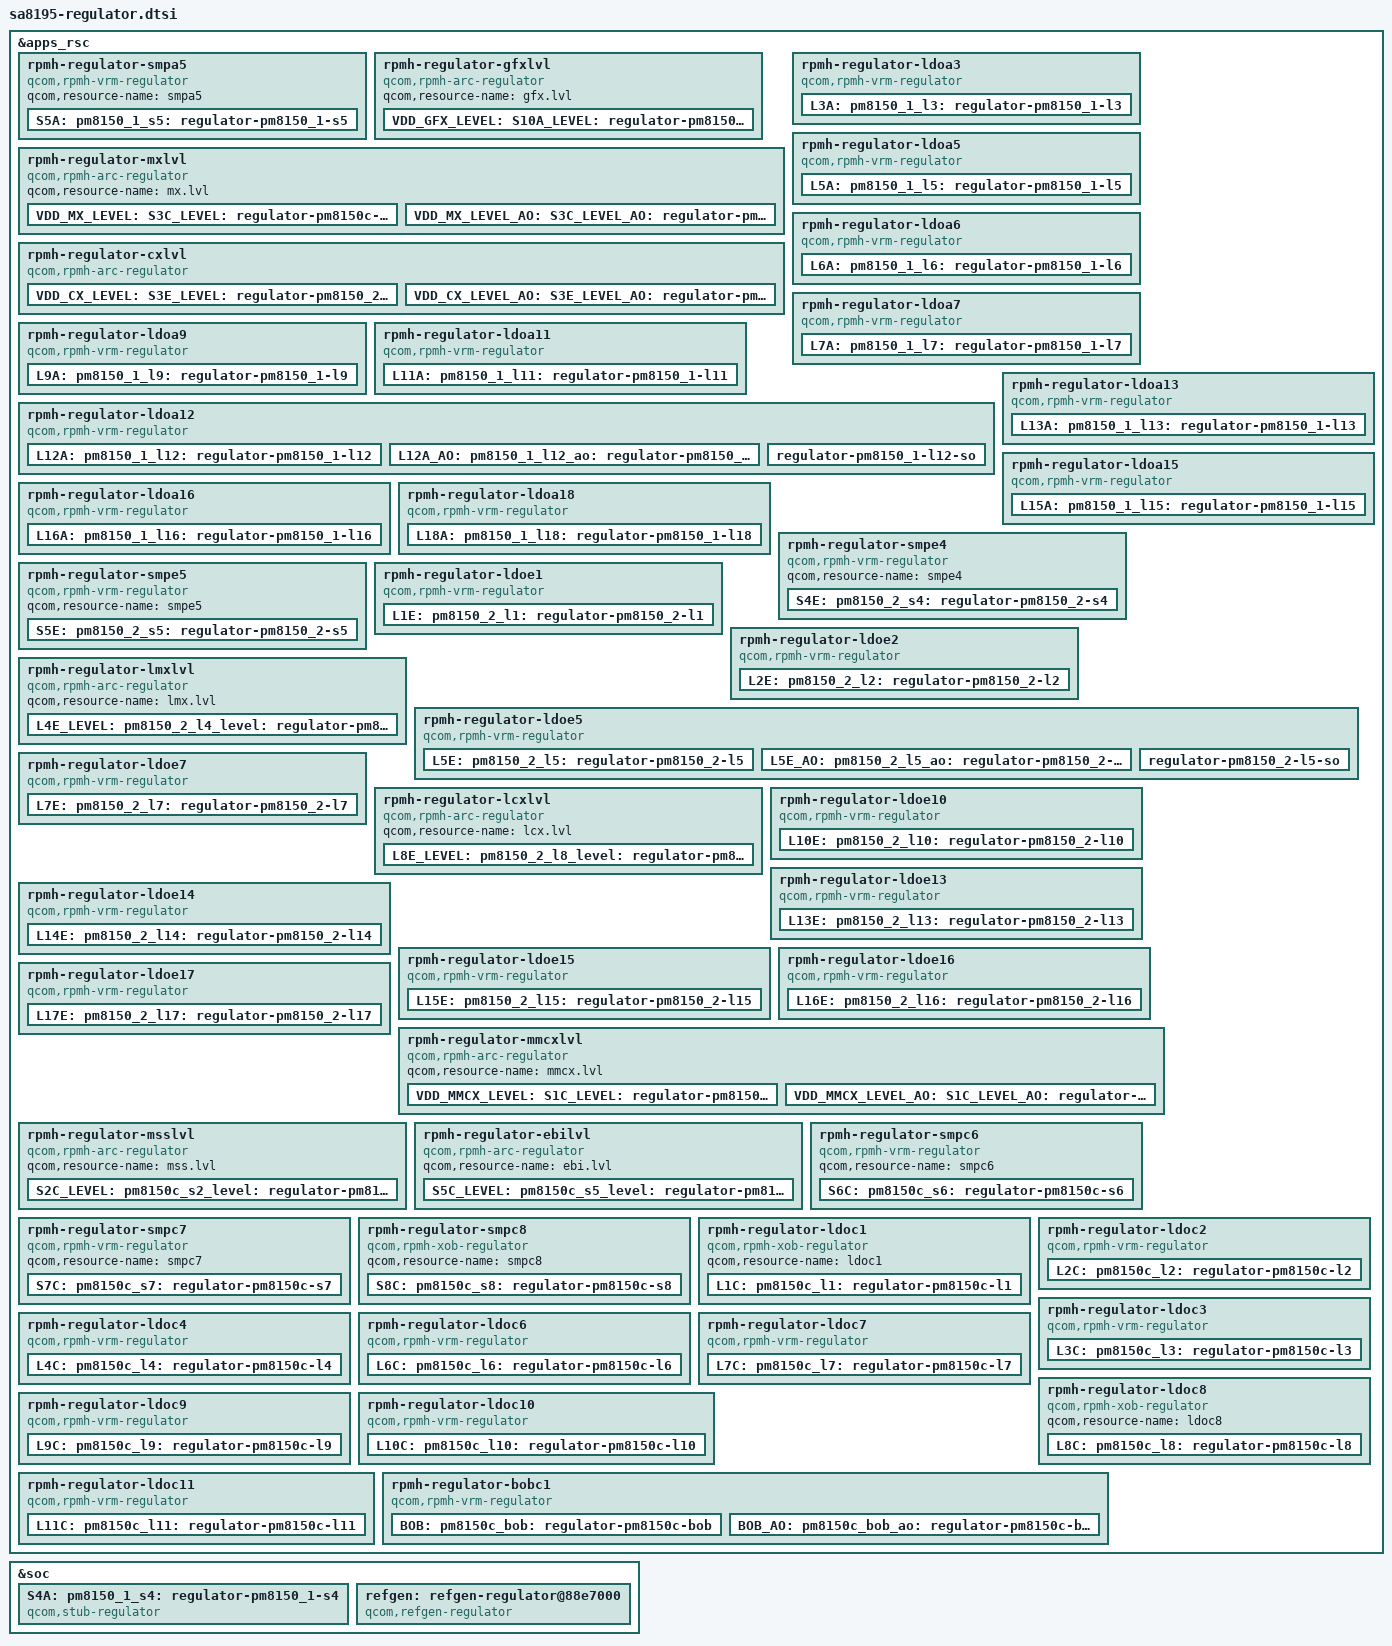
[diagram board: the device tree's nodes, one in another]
#include <dt-bindings/regulator/qcom,rpmh-regulator-levels.h>

&apps_rsc {
	/* PM8150_1 regulators */
	rpmh-regulator-smpa5 {
		compatible = "qcom,rpmh-vrm-regulator";
		qcom,resource-name = "smpa5";
		S5A: pm8150_1_s5: regulator-pm8150_1-s5 {
			regulator-name = "pm8150_1_s5";
			qcom,set = <RPMH_REGULATOR_SET_ALL>;
			regulator-min-microvolt = <1824000>;
			regulator-max-microvolt = <2040000>;
			qcom,init-voltage = <1824000>;
		};
	};

	/* PM8150_1 S10 + S9 + S8 + S7 + S6 = VDD_GFX */
	rpmh-regulator-gfxlvl {
		compatible = "qcom,rpmh-arc-regulator";
		qcom,resource-name = "gfx.lvl";
		VDD_GFX_LEVEL:
		S10A_LEVEL: pm8150_1_s10_level: regulator-pm8150_1-s10-level {
			regulator-name = "pm8150_1_s10_level";
			qcom,set = <RPMH_REGULATOR_SET_ALL>;
			regulator-min-microvolt
				= <RPMH_REGULATOR_LEVEL_RETENTION>;
			regulator-max-microvolt
				= <RPMH_REGULATOR_LEVEL_MAX>;
			qcom,init-voltage-level
				= <RPMH_REGULATOR_LEVEL_RETENTION>;
		};
	};

	/* PM8150C S3 + S4 = VDD_MX supply */
	rpmh-regulator-mxlvl {
		compatible = "qcom,rpmh-arc-regulator";
		qcom,resource-name = "mx.lvl";

		VDD_MX_LEVEL: S3C_LEVEL:
		pm8150c_s3_level: regulator-pm8150c-s3-level {
			regulator-name = "pm8150c_s3_level";
			qcom,set = <RPMH_REGULATOR_SET_ALL>;
			regulator-min-microvolt
				= <RPMH_REGULATOR_LEVEL_RETENTION>;
			regulator-max-microvolt
				= <RPMH_REGULATOR_LEVEL_MAX>;
			qcom,init-voltage-level
				= <RPMH_REGULATOR_LEVEL_RETENTION>;
		};

		VDD_MX_LEVEL_AO: S3C_LEVEL_AO:
		pm8150c_s3_level_ao: regulator-pm8150c-s3-level-ao {
			regulator-name = "pm8150c_s3_level_ao";
			qcom,set = <RPMH_REGULATOR_SET_ACTIVE>;
			regulator-min-microvolt
				= <RPMH_REGULATOR_LEVEL_RETENTION>;
			regulator-max-microvolt
				= <RPMH_REGULATOR_LEVEL_MAX>;
			qcom,init-voltage-level
				= <RPMH_REGULATOR_LEVEL_RETENTION>;
		};
	};

	/* PM8150_2 regulators */
	/* PM8150_2 S3 + S2 + S1 = VDD_CX supply */
	rpmh-regulator-cxlvl {
		compatible = "qcom,rpmh-arc-regulator";
		qcom,resource-name = "cx.lvl";
		pm8150_2_s3_level-parent-supply = <&VDD_MX_LEVEL>;
		pm8150_2_s3_level_ao-parent-supply = <&VDD_MX_LEVEL_AO>;

		VDD_CX_LEVEL: S3E_LEVEL:
		pm8150_2_s3_level: regulator-pm8150_2-s3-level {
			regulator-name = "pm8150_2_s3_level";
			qcom,set = <RPMH_REGULATOR_SET_ALL>;
			regulator-min-microvolt
				= <RPMH_REGULATOR_LEVEL_RETENTION>;
			regulator-max-microvolt
				= <RPMH_REGULATOR_LEVEL_MAX>;
			qcom,init-voltage-level
				= <RPMH_REGULATOR_LEVEL_RETENTION>;
			qcom,min-dropout-voltage-level = <(-1)>;
		};

		VDD_CX_LEVEL_AO: S3E_LEVEL_AO:
		pm8150_2_s3_level_ao: regulator-pm8150_2-s3-level-ao {
			regulator-name = "pm8150_2_s3_level_ao";
			qcom,set = <RPMH_REGULATOR_SET_ACTIVE>;
			regulator-min-microvolt
				= <RPMH_REGULATOR_LEVEL_RETENTION>;
			regulator-max-microvolt
				= <RPMH_REGULATOR_LEVEL_MAX>;
			qcom,init-voltage-level
				= <RPMH_REGULATOR_LEVEL_RETENTION>;
			qcom,min-dropout-voltage-level = <(-1)>;
		};
	};

	rpmh-regulator-ldoa3 {
		compatible = "qcom,rpmh-vrm-regulator";
		qcom,resource-name = "ldoa3";
		qcom,regulator-type = "pmic5-ldo";
		qcom,supported-modes =
			<RPMH_REGULATOR_MODE_LPM
			RPMH_REGULATOR_MODE_HPM>;
		qcom,mode-threshold-currents = <0 10000>;
		L3A: pm8150_1_l3: regulator-pm8150_1-l3 {
			regulator-name = "pm8150_1_l3";
			qcom,set = <RPMH_REGULATOR_SET_ALL>;
			regulator-min-microvolt = <800000>;
			regulator-max-microvolt = <800000>;
			qcom,init-voltage = <800000>;
			qcom,init-mode = <RPMH_REGULATOR_MODE_LPM>;
		};
	};

	rpmh-regulator-ldoa5 {
		compatible = "qcom,rpmh-vrm-regulator";
		qcom,resource-name = "ldoa5";
		qcom,regulator-type = "pmic5-ldo";
		qcom,supported-modes =
			<RPMH_REGULATOR_MODE_LPM
			RPMH_REGULATOR_MODE_HPM>;
		qcom,mode-threshold-currents = <0 1>;
		L5A: pm8150_1_l5: regulator-pm8150_1-l5 {
			regulator-name = "pm8150_1_l5";
			qcom,set = <RPMH_REGULATOR_SET_ALL>;
			regulator-min-microvolt = <480000>;
			regulator-max-microvolt = <932000>;
			qcom,init-voltage = <480000>;
			qcom,init-mode = <RPMH_REGULATOR_MODE_LPM>;
		};
	};

	rpmh-regulator-ldoa6 {
		compatible = "qcom,rpmh-vrm-regulator";
		qcom,resource-name = "ldoa6";
		qcom,regulator-type = "pmic5-ldo";
		qcom,supported-modes =
			<RPMH_REGULATOR_MODE_LPM
			RPMH_REGULATOR_MODE_HPM>;
		qcom,mode-threshold-currents = <0 10000>;
		L6A: pm8150_1_l6: regulator-pm8150_1-l6 {
			regulator-name = "pm8150_1_l6";
			qcom,set = <RPMH_REGULATOR_SET_ALL>;
			regulator-min-microvolt = <1200000>;
			regulator-max-microvolt = <1200000>;
			qcom,init-voltage = <1200000>;
			qcom,init-mode = <RPMH_REGULATOR_MODE_LPM>;
		};
	};

	rpmh-regulator-ldoa7 {
		compatible = "qcom,rpmh-vrm-regulator";
		qcom,resource-name = "ldoa7";
		qcom,regulator-type = "pmic5-ldo";
		qcom,supported-modes =
			<RPMH_REGULATOR_MODE_LPM
			RPMH_REGULATOR_MODE_HPM>;
		qcom,mode-threshold-currents = <0 1>;
		L7A: pm8150_1_l7: regulator-pm8150_1-l7 {
			regulator-name = "pm8150_1_l7";
			qcom,set = <RPMH_REGULATOR_SET_ALL>;
			regulator-min-microvolt = <1800000>;
			regulator-max-microvolt = <1800000>;
			qcom,init-voltage = <1800000>;
			qcom,init-mode = <RPMH_REGULATOR_MODE_LPM>;
		};
	};

	rpmh-regulator-ldoa9 {
		compatible = "qcom,rpmh-vrm-regulator";
		qcom,resource-name = "ldoa9";
		qcom,regulator-type = "pmic5-ldo";
		qcom,supported-modes =
			<RPMH_REGULATOR_MODE_LPM
			RPMH_REGULATOR_MODE_HPM>;
		qcom,mode-threshold-currents = <0 1>;
		L9A: pm8150_1_l9: regulator-pm8150_1-l9 {
			regulator-name = "pm8150_1_l9";
			qcom,set = <RPMH_REGULATOR_SET_ALL>;
			regulator-min-microvolt = <1304000>;
			regulator-max-microvolt = <1304000>;
			qcom,init-voltage = <1304000>;
			qcom,init-mode = <RPMH_REGULATOR_MODE_LPM>;
		};
	};

	rpmh-regulator-ldoa11 {
		compatible = "qcom,rpmh-vrm-regulator";
		qcom,resource-name = "ldoa11";
		qcom,regulator-type = "pmic5-ldo";
		qcom,supported-modes =
			<RPMH_REGULATOR_MODE_LPM
			RPMH_REGULATOR_MODE_HPM>;
		qcom,mode-threshold-currents = <0 10000>;
		L11A: pm8150_1_l11: regulator-pm8150_1-l11 {
			regulator-name = "pm8150_1_l11";
			qcom,set = <RPMH_REGULATOR_SET_ALL>;
			regulator-min-microvolt = <1200000>;
			regulator-max-microvolt = <1200000>;
			qcom,init-voltage = <1200000>;
			qcom,init-mode = <RPMH_REGULATOR_MODE_LPM>;
		};
	};

	rpmh-regulator-ldoa12 {
		compatible = "qcom,rpmh-vrm-regulator";
		qcom,resource-name = "ldoa12";
		qcom,regulator-type = "pmic5-ldo";
		qcom,supported-modes =
			<RPMH_REGULATOR_MODE_LPM
			RPMH_REGULATOR_MODE_HPM>;
		qcom,mode-threshold-currents = <0 1>;
		L12A: pm8150_1_l12: regulator-pm8150_1-l12 {
			regulator-name = "pm8150_1_l12";
			qcom,set = <RPMH_REGULATOR_SET_ALL>;
			regulator-min-microvolt = <1800000>;
			regulator-max-microvolt = <1800000>;
			qcom,init-voltage = <1800000>;
			qcom,init-mode = <RPMH_REGULATOR_MODE_LPM>;
		};

		L12A_AO: pm8150_1_l12_ao: regulator-pm8150_1-l12-ao {
			regulator-name = "pm8150_1_l12_ao";
			qcom,set = <RPMH_REGULATOR_SET_ACTIVE>;
			regulator-min-microvolt = <1800000>;
			regulator-max-microvolt = <1800000>;
			qcom,init-voltage = <1800000>;
			qcom,init-mode = <RPMH_REGULATOR_MODE_LPM>;
		};

		regulator-pm8150_1-l12-so {
			regulator-name = "pm8150_1_l12_so";
			qcom,set = <RPMH_REGULATOR_SET_SLEEP>;
			regulator-min-microvolt = <1800000>;
			regulator-max-microvolt = <1800000>;
			qcom,init-voltage = <1800000>;
			qcom,init-mode = <RPMH_REGULATOR_MODE_LPM>;
			qcom,init-enable = <0>;
		};
	};

	rpmh-regulator-ldoa13 {
		compatible = "qcom,rpmh-vrm-regulator";
		qcom,resource-name = "ldoa13";
		qcom,regulator-type = "pmic5-ldo";
		qcom,supported-modes =
			<RPMH_REGULATOR_MODE_LPM
			RPMH_REGULATOR_MODE_HPM>;
		qcom,mode-threshold-currents = <0 1>;
		L13A: pm8150_1_l13: regulator-pm8150_1-l13 {
			regulator-name = "pm8150_1_l13";
			qcom,set = <RPMH_REGULATOR_SET_ALL>;
			regulator-min-microvolt = <2704000>;
			regulator-max-microvolt = <2704000>;
			qcom,init-voltage = <2704000>;
			qcom,init-mode = <RPMH_REGULATOR_MODE_LPM>;
		};
	};

	rpmh-regulator-ldoa15 {
		compatible = "qcom,rpmh-vrm-regulator";
		qcom,resource-name = "ldoa15";
		qcom,regulator-type = "pmic5-ldo";
		qcom,supported-modes =
			<RPMH_REGULATOR_MODE_LPM
			RPMH_REGULATOR_MODE_HPM>;
		qcom,mode-threshold-currents = <0 1>;
		L15A: pm8150_1_l15: regulator-pm8150_1-l15 {
			regulator-name = "pm8150_1_l15";
			qcom,set = <RPMH_REGULATOR_SET_ALL>;
			regulator-min-microvolt = <1704000>;
			regulator-max-microvolt = <1704000>;
			qcom,init-voltage = <1704000>;
			qcom,init-mode = <RPMH_REGULATOR_MODE_LPM>;
		};
	};

	rpmh-regulator-ldoa16 {
		compatible = "qcom,rpmh-vrm-regulator";
		qcom,resource-name = "ldoa16";
		qcom,regulator-type = "pmic5-ldo";
		qcom,supported-modes =
			<RPMH_REGULATOR_MODE_LPM
			RPMH_REGULATOR_MODE_HPM>;
		qcom,mode-threshold-currents = <0 1>;
		L16A: pm8150_1_l16: regulator-pm8150_1-l16 {
			regulator-name = "pm8150_1_l16";
			qcom,set = <RPMH_REGULATOR_SET_ALL>;
			regulator-min-microvolt = <2704000>;
			regulator-max-microvolt = <2960000>;
			qcom,init-voltage = <2704000>;
			qcom,init-mode = <RPMH_REGULATOR_MODE_LPM>;
		};
	};

	rpmh-regulator-ldoa18 {
		compatible = "qcom,rpmh-vrm-regulator";
		qcom,resource-name = "ldoa18";
		qcom,regulator-type = "pmic5-ldo";
		qcom,supported-modes =
			<RPMH_REGULATOR_MODE_LPM
			RPMH_REGULATOR_MODE_HPM>;
		qcom,mode-threshold-currents = <0 1>;
		L18A: pm8150_1_l18: regulator-pm8150_1-l18 {
			regulator-name = "pm8150_1_l18";
			qcom,set = <RPMH_REGULATOR_SET_ALL>;
			regulator-min-microvolt = <880000>;
			regulator-max-microvolt = <880000>;
			qcom,init-voltage = <880000>;
			qcom,init-mode = <RPMH_REGULATOR_MODE_LPM>;
		};
	};

	rpmh-regulator-smpe4 {
		compatible = "qcom,rpmh-vrm-regulator";
		qcom,resource-name = "smpe4";
		S4E: pm8150_2_s4: regulator-pm8150_2-s4 {
			regulator-name = "pm8150_2_s4";
			qcom,set = <RPMH_REGULATOR_SET_ALL>;
			regulator-min-microvolt = <752000>;
			regulator-max-microvolt = <1128000>;
			qcom,init-voltage = <752000>;
		};
	};

	rpmh-regulator-smpe5 {
		compatible = "qcom,rpmh-vrm-regulator";
		qcom,resource-name = "smpe5";
		S5E: pm8150_2_s5: regulator-pm8150_2-s5 {
			regulator-name = "pm8150_2_s5";
			qcom,set = <RPMH_REGULATOR_SET_ALL>;
			regulator-min-microvolt = <1824000>;
			regulator-max-microvolt = <2040000>;
			qcom,init-voltage = <1824000>;
		};
	};

	rpmh-regulator-ldoe1 {
		compatible = "qcom,rpmh-vrm-regulator";
		qcom,resource-name = "ldoe1";
		qcom,regulator-type = "pmic5-ldo";
		qcom,supported-modes =
			<RPMH_REGULATOR_MODE_LPM
			RPMH_REGULATOR_MODE_HPM>;
		qcom,mode-threshold-currents = <0 1>;
		L1E: pm8150_2_l1: regulator-pm8150_2-l1 {
			regulator-name = "pm8150_2_l1";
			qcom,set = <RPMH_REGULATOR_SET_ALL>;
			regulator-min-microvolt = <752000>;
			regulator-max-microvolt = <752000>;
			qcom,init-voltage = <752000>;
			qcom,init-mode = <RPMH_REGULATOR_MODE_LPM>;
		};
	};

	rpmh-regulator-ldoe2 {
		compatible = "qcom,rpmh-vrm-regulator";
		qcom,resource-name = "ldoe2";
		qcom,regulator-type = "pmic5-ldo";
		qcom,supported-modes =
			<RPMH_REGULATOR_MODE_LPM
			RPMH_REGULATOR_MODE_HPM>;
		qcom,mode-threshold-currents = <0 1>;
		L2E: pm8150_2_l2: regulator-pm8150_2-l2 {
			regulator-name = "pm8150_2_l2";
			qcom,set = <RPMH_REGULATOR_SET_ALL>;
			regulator-min-microvolt = <1704000>;
			regulator-max-microvolt = <2928000>;
			qcom,init-voltage = <1704000>;
			qcom,init-mode = <RPMH_REGULATOR_MODE_LPM>;
		};
	};

	rpmh-regulator-lmxlvl {
		compatible = "qcom,rpmh-arc-regulator";
		qcom,resource-name = "lmx.lvl";
		L4E_LEVEL: pm8150_2_l4_level: regulator-pm8150_2-l4-level {
			regulator-name = "pm8150_2_l4_level";
			qcom,set = <RPMH_REGULATOR_SET_ALL>;
			regulator-min-microvolt =
				<RPMH_REGULATOR_LEVEL_RETENTION>;
			regulator-max-microvolt =
				<RPMH_REGULATOR_LEVEL_MAX>;
			qcom,init-voltage-level =
				<RPMH_REGULATOR_LEVEL_RETENTION>;
		};
	};

	rpmh-regulator-ldoe5 {
		compatible = "qcom,rpmh-vrm-regulator";
		qcom,resource-name = "ldoe5";
		qcom,regulator-type = "pmic5-ldo";
		qcom,supported-modes =
			<RPMH_REGULATOR_MODE_LPM
			RPMH_REGULATOR_MODE_HPM>;
		qcom,mode-threshold-currents = <0 1>;
		L5E: pm8150_2_l5: regulator-pm8150_2-l5 {
			regulator-name = "pm8150_2_l5";
			qcom,set = <RPMH_REGULATOR_SET_ALL>;
			regulator-min-microvolt = <880000>;
			regulator-max-microvolt = <880000>;
			qcom,init-voltage = <880000>;
			qcom,init-mode = <RPMH_REGULATOR_MODE_LPM>;
		};

		L5E_AO: pm8150_2_l5_ao: regulator-pm8150_2-l5-ao {
			regulator-name = "pm8150_2_l5_ao";
			qcom,set = <RPMH_REGULATOR_SET_ACTIVE>;
			regulator-min-microvolt = <880000>;
			regulator-max-microvolt = <880000>;
			qcom,init-voltage = <880000>;
			qcom,init-mode = <RPMH_REGULATOR_MODE_LPM>;
		};

		regulator-pm8150_2-l5-so {
			regulator-name = "pm8150_2_l5_so";
			qcom,set = <RPMH_REGULATOR_SET_SLEEP>;
			regulator-min-microvolt = <880000>;
			regulator-max-microvolt = <880000>;
			qcom,init-voltage = <880000>;
			qcom,init-mode = <RPMH_REGULATOR_MODE_LPM>;
			qcom,init-enable = <0>;
		};

	};

	rpmh-regulator-ldoe7 {
		compatible = "qcom,rpmh-vrm-regulator";
		qcom,resource-name = "ldoe7";
		qcom,regulator-type = "pmic5-ldo";
		qcom,supported-modes =
			<RPMH_REGULATOR_MODE_LPM
			RPMH_REGULATOR_MODE_HPM>;
		qcom,mode-threshold-currents = <0 1>;
		L7E: pm8150_2_l7: regulator-pm8150_2-l7 {
			regulator-name = "pm8150_2_l7";
			qcom,set = <RPMH_REGULATOR_SET_ALL>;
			regulator-min-microvolt = <1800000>;
			regulator-max-microvolt = <1800000>;
			qcom,init-voltage = <1800000>;
			qcom,init-mode = <RPMH_REGULATOR_MODE_LPM>;
		};
	};

	rpmh-regulator-lcxlvl {
		compatible = "qcom,rpmh-arc-regulator";
		qcom,resource-name = "lcx.lvl";
		L8E_LEVEL: pm8150_2_l8_level: regulator-pm8150_2-l8-level {
			regulator-name = "pm8150_2_l8_level";
			qcom,set = <RPMH_REGULATOR_SET_ALL>;
			regulator-min-microvolt
				= <RPMH_REGULATOR_LEVEL_RETENTION>;
			regulator-max-microvolt
				= <RPMH_REGULATOR_LEVEL_MAX>;
			qcom,init-voltage-level
				= <RPMH_REGULATOR_LEVEL_RETENTION>;
		};
	};

	rpmh-regulator-ldoe10 {
		compatible = "qcom,rpmh-vrm-regulator";
		qcom,resource-name = "ldoe10";
		qcom,regulator-type = "pmic5-ldo";
		qcom,supported-modes =
			<RPMH_REGULATOR_MODE_LPM
			RPMH_REGULATOR_MODE_HPM>;
		qcom,mode-threshold-currents = <0 10000>;
		L10E: pm8150_2_l10: regulator-pm8150_2-l10 {
			regulator-name = "pm8150_2_l10";
			qcom,set = <RPMH_REGULATOR_SET_ALL>;
			regulator-min-microvolt = <2504000>;
			regulator-max-microvolt = <2960000>;
			qcom,init-voltage = <2504000>;
			qcom,init-mode = <RPMH_REGULATOR_MODE_LPM>;
		};
	};

	rpmh-regulator-ldoe13 {
		compatible = "qcom,rpmh-vrm-regulator";
		qcom,resource-name = "ldoe13";
		qcom,regulator-type = "pmic5-ldo";
		qcom,supported-modes =
			<RPMH_REGULATOR_MODE_LPM
			RPMH_REGULATOR_MODE_HPM>;
		qcom,mode-threshold-currents = <0 1>;
		L13E: pm8150_2_l13: regulator-pm8150_2-l13 {
			regulator-name = "pm8150_2_l13";
			qcom,set = <RPMH_REGULATOR_SET_ALL>;
			regulator-min-microvolt = <1704000>;
			regulator-max-microvolt = <2928000>;
			qcom,init-voltage = <1704000>;
			qcom,init-mode = <RPMH_REGULATOR_MODE_LPM>;
		};
	};

	rpmh-regulator-ldoe14 {
		compatible = "qcom,rpmh-vrm-regulator";
		qcom,resource-name = "ldoe14";
		qcom,regulator-type = "pmic5-ldo";
		qcom,supported-modes =
			<RPMH_REGULATOR_MODE_LPM
			RPMH_REGULATOR_MODE_HPM>;
		qcom,mode-threshold-currents = <0 1>;
		L14E: pm8150_2_l14: regulator-pm8150_2-l14 {
			regulator-name = "pm8150_2_l14";
			qcom,set = <RPMH_REGULATOR_SET_ALL>;
			regulator-min-microvolt = <1800000>;
			regulator-max-microvolt = <1800000>;
			qcom,init-voltage = <1800000>;
			qcom,init-mode = <RPMH_REGULATOR_MODE_LPM>;
		};
	};

	rpmh-regulator-ldoe15 {
		compatible = "qcom,rpmh-vrm-regulator";
		qcom,resource-name = "ldoe15";
		qcom,regulator-type = "pmic5-ldo";
		qcom,supported-modes =
			<RPMH_REGULATOR_MODE_LPM
			RPMH_REGULATOR_MODE_HPM>;
		qcom,mode-threshold-currents = <0 10000>;
		L15E: pm8150_2_l15: regulator-pm8150_2-l15 {
			regulator-name = "pm8150_2_l15";
			qcom,set = <RPMH_REGULATOR_SET_ALL>;
			regulator-min-microvolt = <1800000>;
			regulator-max-microvolt = <1800000>;
			qcom,init-voltage = <1800000>;
			qcom,init-mode = <RPMH_REGULATOR_MODE_LPM>;
		};
	};

	rpmh-regulator-ldoe16 {
		compatible = "qcom,rpmh-vrm-regulator";
		qcom,resource-name = "ldoe16";
		qcom,regulator-type = "pmic5-ldo";
		qcom,supported-modes =
			<RPMH_REGULATOR_MODE_LPM
			RPMH_REGULATOR_MODE_HPM>;
		qcom,mode-threshold-currents = <0 10000>;
		L16E: pm8150_2_l16: regulator-pm8150_2-l16 {
			regulator-name = "pm8150_2_l16";
			qcom,set = <RPMH_REGULATOR_SET_ALL>;
			regulator-min-microvolt = <3072000>;
			regulator-max-microvolt = <3072000>;
			qcom,init-voltage = <3072000>;
			qcom,init-mode = <RPMH_REGULATOR_MODE_LPM>;
		};
	};

	rpmh-regulator-ldoe17 {
		compatible = "qcom,rpmh-vrm-regulator";
		qcom,resource-name = "ldoe17";
		qcom,regulator-type = "pmic5-ldo";
		qcom,supported-modes =
			<RPMH_REGULATOR_MODE_LPM
			RPMH_REGULATOR_MODE_HPM>;
		qcom,mode-threshold-currents = <0 10000>;
		L17E: pm8150_2_l17: regulator-pm8150_2-l17 {
			regulator-name = "pm8150_2_l17";
			qcom,set = <RPMH_REGULATOR_SET_ALL>;
			regulator-min-microvolt = <2960000>;
			regulator-max-microvolt = <2960000>;
			qcom,init-voltage = <2960000>;
			qcom,init-mode = <RPMH_REGULATOR_MODE_LPM>;
		};
	};

	/* PM8150C regulators */

	/* PM8150C S1 = VDD_MMCX supply */
	rpmh-regulator-mmcxlvl {
		compatible = "qcom,rpmh-arc-regulator";
		qcom,resource-name = "mmcx.lvl";

		VDD_MMCX_LEVEL:
		S1C_LEVEL: pm8150c_s1_level: regulator-pm8150c-s1-level {
			regulator-name = "pm8150c_s1_level";
			qcom,set = <RPMH_REGULATOR_SET_ALL>;
			regulator-min-microvolt
				= <RPMH_REGULATOR_LEVEL_LOW_SVS>;
			regulator-max-microvolt
				= <RPMH_REGULATOR_LEVEL_MAX>;
			qcom,init-voltage-level
				= <RPMH_REGULATOR_LEVEL_LOW_SVS>;
		};

		VDD_MMCX_LEVEL_AO: S1C_LEVEL_AO:
		pm8150c_s1_level_ao: regulator-pm8150c-s1-level-ao {
			regulator-name = "pm8150c_s1_level_ao";
			qcom,set = <RPMH_REGULATOR_SET_ACTIVE>;
			regulator-min-microvolt
				= <RPMH_REGULATOR_LEVEL_LOW_SVS>;
			regulator-max-microvolt
				= <RPMH_REGULATOR_LEVEL_MAX>;
			qcom,init-voltage-level
				= <RPMH_REGULATOR_LEVEL_LOW_SVS>;
		};
	};

	/* PM8150C S2 = VDD_MODEM supply */
	rpmh-regulator-msslvl {
		compatible = "qcom,rpmh-arc-regulator";
		qcom,resource-name = "mss.lvl";
		S2C_LEVEL: pm8150c_s2_level: regulator-pm8150c-s2-level {
			regulator-name = "pm8150c_s2_level";
			qcom,set = <RPMH_REGULATOR_SET_ALL>;
			regulator-min-microvolt
				= <RPMH_REGULATOR_LEVEL_RETENTION>;
			regulator-max-microvolt
				= <RPMH_REGULATOR_LEVEL_MAX>;
			qcom,init-voltage-level
				= <RPMH_REGULATOR_LEVEL_RETENTION>;
		};
	};

	/* PM8150C S5 = VDDA_EBI supply */
	rpmh-regulator-ebilvl {
		compatible = "qcom,rpmh-arc-regulator";
		qcom,resource-name = "ebi.lvl";
		S5C_LEVEL: pm8150c_s5_level: regulator-pm8150c-s5-level {
			regulator-name = "pm8150c_s5_level";
			qcom,set = <RPMH_REGULATOR_SET_ALL>;
			regulator-min-microvolt
				= <RPMH_REGULATOR_LEVEL_RETENTION>;
			regulator-max-microvolt
				= <RPMH_REGULATOR_LEVEL_MAX>;
			qcom,init-voltage-level
				= <RPMH_REGULATOR_LEVEL_RETENTION>;
		};
	};

	rpmh-regulator-smpc6 {
		compatible = "qcom,rpmh-vrm-regulator";
		qcom,resource-name = "smpc6";
		S6C: pm8150c_s6: regulator-pm8150c-s6 {
			regulator-name = "pm8150c-s6";
			qcom,set = <RPMH_REGULATOR_SET_ALL>;
			regulator-min-microvolt = <1260000>;
			regulator-max-microvolt = <1396000>;
			qcom,init-voltage = <1260000>;
		};
	};

	rpmh-regulator-smpc7 {
		compatible = "qcom,rpmh-vrm-regulator";
		qcom,resource-name = "smpc7";
		S7C: pm8150c_s7: regulator-pm8150c-s7 {
			regulator-name = "pm8150c-s7";
			qcom,set = <RPMH_REGULATOR_SET_ALL>;
			regulator-min-microvolt = <800000>;
			regulator-max-microvolt = <1128000>;
			qcom,init-voltage = <800000>;
		};
	};

	rpmh-regulator-smpc8 {
		compatible = "qcom,rpmh-xob-regulator";
		qcom,resource-name = "smpc8";
		S8C: pm8150c_s8: regulator-pm8150c-s8 {
			regulator-name = "pm8150c_s8";
			qcom,set = <RPMH_REGULATOR_SET_ALL>;
			regulator-min-microvolt = <1800000>;
			regulator-max-microvolt = <1800000>;
		};
	};

	rpmh-regulator-ldoc1 {
		compatible = "qcom,rpmh-xob-regulator";
		qcom,resource-name = "ldoc1";
		L1C: pm8150c_l1: regulator-pm8150c-l1 {
			regulator-name = "pm8150c_l1";
			qcom,set = <RPMH_REGULATOR_SET_ALL>;
			regulator-min-microvolt = <1800000>;
			regulator-max-microvolt = <1800000>;
		};
	};

	rpmh-regulator-ldoc2 {
		compatible = "qcom,rpmh-vrm-regulator";
		qcom,resource-name = "ldoc2";
		qcom,regulator-type = "pmic5-ldo";
		qcom,supported-modes =
			<RPMH_REGULATOR_MODE_LPM
			RPMH_REGULATOR_MODE_HPM>;
		qcom,mode-threshold-currents = <0 30000>;
		L2C: pm8150c_l2: regulator-pm8150c-l2 {
			regulator-name = "pm8150c_l2";
			qcom,set = <RPMH_REGULATOR_SET_ALL>;
			regulator-min-microvolt = <1200000>;
			regulator-max-microvolt = <1200000>;
			qcom,init-voltage = <1200000>;
			qcom,init-mode = <RPMH_REGULATOR_MODE_LPM>;
		};
	};

	rpmh-regulator-ldoc3 {
		compatible = "qcom,rpmh-vrm-regulator";
		qcom,resource-name = "ldoc3";
		qcom,regulator-type = "pmic5-ldo";
		qcom,supported-modes =
			<RPMH_REGULATOR_MODE_LPM
			RPMH_REGULATOR_MODE_HPM>;
		qcom,mode-threshold-currents = <0 1>;
		L3C: pm8150c_l3: regulator-pm8150c-l3 {
			regulator-name = "pm8150c_l3";
			qcom,set = <RPMH_REGULATOR_SET_ALL>;
			regulator-min-microvolt = <1200000>;
			regulator-max-microvolt = <1200000>;
			qcom,init-voltage = <1200000>;
			qcom,init-mode = <RPMH_REGULATOR_MODE_LPM>;
		};
	};

	rpmh-regulator-ldoc4 {
		compatible = "qcom,rpmh-vrm-regulator";
		qcom,resource-name = "ldoc4";
		qcom,regulator-type = "pmic5-ldo";
		qcom,supported-modes =
			<RPMH_REGULATOR_MODE_LPM
			RPMH_REGULATOR_MODE_HPM>;
		qcom,mode-threshold-currents = <0 1>;
		L4C: pm8150c_l4: regulator-pm8150c-l4 {
			regulator-name = "pm8150c_l4";
			qcom,set = <RPMH_REGULATOR_SET_ALL>;
			regulator-min-microvolt = <2856000>;
			regulator-max-microvolt = <3008000>;
			qcom,init-voltage = <2856000>;
			qcom,init-mode = <RPMH_REGULATOR_MODE_LPM>;
		};
	};

	rpmh-regulator-ldoc6 {
		compatible = "qcom,rpmh-vrm-regulator";
		qcom,resource-name = "ldoc6";
		qcom,regulator-type = "pmic5-ldo";
		qcom,supported-modes =
			<RPMH_REGULATOR_MODE_LPM
			RPMH_REGULATOR_MODE_HPM>;
		qcom,mode-threshold-currents = <0 1>;
		L6C: pm8150c_l6: regulator-pm8150c-l6 {
			regulator-name = "pm8150c_l6";
			qcom,set = <RPMH_REGULATOR_SET_ALL>;
			regulator-min-microvolt = <1800000>;
			regulator-max-microvolt = <2960000>;
			qcom,init-voltage = <1800000>;
			qcom,init-mode = <RPMH_REGULATOR_MODE_LPM>;
		};
	};

	rpmh-regulator-ldoc7 {
		compatible = "qcom,rpmh-vrm-regulator";
		qcom,resource-name = "ldoc7";
		qcom,regulator-type = "pmic5-ldo";
		qcom,supported-modes =
			<RPMH_REGULATOR_MODE_LPM
			RPMH_REGULATOR_MODE_HPM>;
		qcom,mode-threshold-currents = <0 1>;
		L7C: pm8150c_l7: regulator-pm8150c-l7 {
			regulator-name = "pm8150c_l7";
			qcom,set = <RPMH_REGULATOR_SET_ALL>;
			regulator-min-microvolt = <2856000>;
			regulator-max-microvolt = <3104000>;
			qcom,init-voltage = <2856000>;
			qcom,init-mode = <RPMH_REGULATOR_MODE_LPM>;
		};
	};

	rpmh-regulator-ldoc8 {
		compatible = "qcom,rpmh-xob-regulator";
		qcom,resource-name = "ldoc8";
		L8C: pm8150c_l8: regulator-pm8150c-l8 {
			regulator-name = "pm8150c_l8";
			qcom,set = <RPMH_REGULATOR_SET_ALL>;
			regulator-min-microvolt = <1800000>;
			regulator-max-microvolt = <1800000>;
		};
	};

	rpmh-regulator-ldoc9 {
		compatible = "qcom,rpmh-vrm-regulator";
		qcom,resource-name = "ldoc9";
		qcom,regulator-type = "pmic5-ldo";
		qcom,supported-modes =
			<RPMH_REGULATOR_MODE_LPM
			RPMH_REGULATOR_MODE_HPM>;
		qcom,mode-threshold-currents = <0 10000>;
		L9C: pm8150c_l9: regulator-pm8150c-l9 {
			regulator-name = "pm8150c_l9";
			qcom,set = <RPMH_REGULATOR_SET_ALL>;
			regulator-min-microvolt = <2504000>;
			regulator-max-microvolt = <2960000>;
			qcom,init-voltage = <2504000>;
			qcom,init-mode = <RPMH_REGULATOR_MODE_LPM>;
		};
	};

	rpmh-regulator-ldoc10 {
		compatible = "qcom,rpmh-vrm-regulator";
		qcom,resource-name = "ldoc10";
		qcom,regulator-type = "pmic5-ldo";
		qcom,supported-modes =
			<RPMH_REGULATOR_MODE_LPM
			RPMH_REGULATOR_MODE_HPM>;
		qcom,mode-threshold-currents = <0 1>;
		L10C: pm8150c_l10: regulator-pm8150c-l10 {
			regulator-name = "pm8150c_l10";
			qcom,set = <RPMH_REGULATOR_SET_ALL>;
			regulator-min-microvolt = <3000000>;
			regulator-max-microvolt = <3312000>;
			qcom,init-voltage = <3000000>;
			qcom,init-mode = <RPMH_REGULATOR_MODE_LPM>;
		};
	};

	rpmh-regulator-ldoc11 {
		compatible = "qcom,rpmh-vrm-regulator";
		qcom,resource-name = "ldoc11";
		qcom,regulator-type = "pmic5-ldo";
		qcom,supported-modes =
			<RPMH_REGULATOR_MODE_LPM
			RPMH_REGULATOR_MODE_HPM>;
		qcom,mode-threshold-currents = <0 1>;
		L11C: pm8150c_l11: regulator-pm8150c-l11 {
			regulator-name = "pm8150c_l11";
			qcom,set = <RPMH_REGULATOR_SET_ALL>;
			regulator-min-microvolt = <3000000>;
			regulator-max-microvolt = <3312000>;
			qcom,init-voltage = <3000000>;
			qcom,init-mode = <RPMH_REGULATOR_MODE_LPM>;
		};
	};

	rpmh-regulator-bobc1 {
		compatible = "qcom,rpmh-vrm-regulator";
		qcom,resource-name = "bobc1";
		qcom,regulator-type = "pmic5-bob";
		qcom,send-defaults;

		BOB: pm8150c_bob: regulator-pm8150c-bob {
			regulator-name = "pm8150c_bob";
			qcom,set = <RPMH_REGULATOR_SET_ALL>;
			regulator-min-microvolt = <3296000>;
			regulator-max-microvolt = <3960000>;
			qcom,init-voltage = <3296000>;
			qcom,init-mode = <RPMH_REGULATOR_MODE_PASS>;
		};

		BOB_AO: pm8150c_bob_ao: regulator-pm8150c-bob-ao {
			regulator-name = "pm8150c_bob_ao";
			qcom,set = <RPMH_REGULATOR_SET_ACTIVE>;
			regulator-min-microvolt = <3296000>;
			regulator-max-microvolt = <3960000>;
			qcom,init-voltage = <3296000>;
			qcom,init-mode = <RPMH_REGULATOR_MODE_AUTO>;
		};
	};
};

&soc {
	/* Stub regulators */

	/*
	 * RPMh does not provide support for PM8150_1 S4. Therefore,
	 * use a stub regulator for S4.
	 */
	S4A: pm8150_1_s4: regulator-pm8150_1-s4 {
		compatible = "qcom,stub-regulator";
		regulator-name = "pm8150_1_s4";
		qcom,hpm-min-load = <100000>;
		regulator-min-microvolt = <1800000>;
		regulator-max-microvolt = <1800000>;
	};

	refgen: refgen-regulator@88e7000 {
		compatible = "qcom,refgen-regulator";
		reg = <0x88e7000 0x60>;
		regulator-name = "refgen";
		regulator-enable-ramp-delay = <5>;
	};
};
